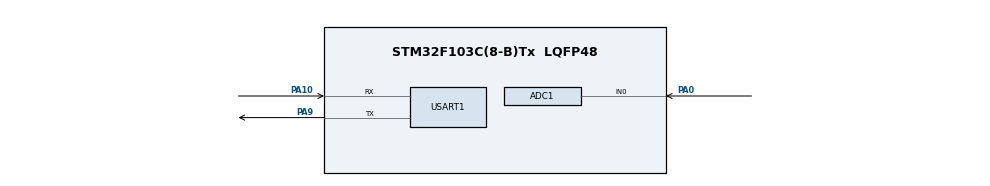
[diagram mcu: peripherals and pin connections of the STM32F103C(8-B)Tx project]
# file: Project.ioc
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ADC1.Channel-0\#ChannelRegularConversion=ADC_CHANNEL_0
ADC1.ContinuousConvMode=DISABLE
ADC1.ExternalTrigConv=ADC_EXTERNALTRIGCONV_T3_TRGO
ADC1.InjNumberOfConversion=0
ADC1.NbrOfConversion=1
ADC1.NbrOfConversionFlag=1
ADC1.Rank-0\#ChannelRegularConversion=1
ADC1.SamplingTime-0\#ChannelRegularConversion=ADC_SAMPLETIME_1CYCLE_5
ADC1.master=1
Mcu.Family=STM32F1
Mcu.Name=STM32F103C(8-B)Tx
Mcu.Package=LQFP48
NVIC.ADC1_2_IRQn=true\:0\:0\:false\:false\:true\:true\:true
NVIC.PriorityGroup=NVIC_PRIORITYGROUP_4
NVIC.TIM2_IRQn=true\:0\:0\:false\:false\:true\:true\:true
NVIC.USART1_IRQn=true\:0\:0\:false\:false\:true\:true\:true
PA0-WKUP.Signal=ADCx_IN0
PA10.Mode=Asynchronous
PA10.Signal=USART1_RX
PA13.Mode=Serial_Wire
PA13.Signal=SYS_JTMS-SWDIO
PA14.Mode=Serial_Wire
PA14.Signal=SYS_JTCK-SWCLK
PA9.Mode=Asynchronous
PA9.Signal=USART1_TX
ProjectManager.HeapSize=0x200
ProjectManager.StackSize=0x400
ProjectManager.TargetToolchain=MDK-ARM V5
RCC.APB1Freq_Value=8000000
RCC.APB2Freq_Value=8000000
SH.ADCx_IN0.0=ADC1_IN0,IN0
TIM2.CounterMode=TIM_COUNTERMODE_UP
TIM2.Period=60000
TIM2.Prescaler=8000
TIM2.TIM_MasterOutputTrigger=TIM_TRGO_RESET
TIM3.Period=1
TIM3.Prescaler=3999
TIM3.TIM_MasterOutputTrigger=TIM_TRGO_UPDATE
USART1.VirtualMode=VM_ASYNC
VP_TIM2_VS_ClockSourceINT.Mode=Internal
VP_TIM3_VS_ClockSourceINT.Mode=Internal
board=custom

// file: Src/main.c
/* USER CODE BEGIN Header */
/**
  ******************************************************************************
  * @file           : main.c
  * @brief          : Main program body
  ******************************************************************************
  * @attention
  *
  * <h2><center>&copy; Copyright (c) 2020 STMicroelectronics.
  * All rights reserved.</center></h2>
  *
  * This software component is licensed by ST under BSD 3-Clause license,
  * the "License"; You may not use this file except in compliance with the
  * License. You may obtain a copy of the License at:
  *                        opensource.org/licenses/BSD-3-Clause
  *
  ******************************************************************************
  */
/* USER CODE END Header */

#include "main.h"

/* USER CODE BEGIN Includes */
#include <stdio.h>
#include <stdlib.h>
#include <string.h>
/* USER CODE END Includes */

/* USER CODE BEGIN PM */
#define MAX_UART 16
#define COMMAND_LENGTH 5
#define ADC_BUFFER_SIZE 32
#define PEAK_THRESHOLD 2000
#define MIN_RR_INTERVAL 0.6
#define MIN_SAMPLES_RR 32

/* USER CODE END PM */

ADC_HandleTypeDef hadc1;

TIM_HandleTypeDef htim2;
TIM_HandleTypeDef htim3;

UART_HandleTypeDef huart1;

/* USER CODE BEGIN PV */
uint32_t adc_value;
char value[16];
char rxBuffer[16];

int set_sample_rate = 0;
int compute_bpm = 0;
int collect_data = 0;

int new_sample_rate = 1000;
int new_counter_period = 2;
const int counter_clk = 2000;
int computed_bpm = 0;

int detect_peak = 0;
int transmit_adc = 0;

int sample_count = 0;

uint32_t adc_values [32];
int seeker = 0, count = 0;
float prev_peak = 0, curr_peak = 0;
int num_peaks = 0;
float peak_distance = 0;

int transmit_bpm = 0;
/* USER CODE END PV */

void SystemClock_Config(void);
static void MX_GPIO_Init(void);
static void MX_ADC1_Init(void);
static void MX_USART1_UART_Init(void);
static void MX_TIM3_Init(void);
static void MX_TIM2_Init(void);

/* USER CODE BEGIN 0 */
void decode(){
	// fixed length commands
	char command [COMMAND_LENGTH+1] = {rxBuffer[0],
	rxBuffer[1], rxBuffer[2], rxBuffer[3], rxBuffer[4], '\0'};
	if(strcmp(command, "rate=") == 0){
		// set new sample rate
		char sample_rate_str [MAX_UART];
		for (int i= COMMAND_LENGTH; i<MAX_UART; i++){
				if(rxBuffer[i] != ';')
					sample_rate_str[i-COMMAND_LENGTH] = rxBuffer[i];
				else
				{
					sample_rate_str[i-COMMAND_LENGTH] = '\0';
					break;
				}
		}
		set_sample_rate = 1;
		new_sample_rate = atoi(sample_rate_str);
	} else if (strcmp(command, "hbpm;") == 0){
		// compute heart beats
		compute_bpm = 1;
	} else if (strcmp(command, "data;") == 0){
		// collect one minute of data
		collect_data = 1;
	}
	else {
		// Invalid command
	}
}
char bpm[24];
void countPeaks(){
	if((adc_values[count-1] > adc_values[count-2]) &&
		(adc_values[count-1] > adc_values[count])){    // if the previous point is a local maximamum; compare it to its neighbors
			if(adc_values[count-1] > PEAK_THRESHOLD ){  // if the previous point is above the specified threshold
						curr_peak = __HAL_TIM_GET_COUNTER(&htim2) / 1000.0; // get current time for the one minute timer
						peak_distance = curr_peak - prev_peak;              // Compute RR-Interval
						if(peak_distance > MIN_RR_INTERVAL){                // if the RR-Interval is above the minimum RR-Interval; a sort of debouncing/LPF
								num_peaks++;                                    // count it as a peak
								if (num_peaks >= 2) {
									computed_bpm = 60.0 / (peak_distance);         // 300-method for calculating bpm
									transmit_bpm = 1;
									sprintf(bpm, "bpm: %d\n\r", computed_bpm);
									HAL_UART_Transmit(&huart1, (uint8_t *)bpm, strlen(bpm), 10);
								}
								prev_peak = curr_peak;
						}
			}
		}
}
void HAL_ADC_ConvCpltCallback(ADC_HandleTypeDef* hadc){
	if(hadc->Instance == ADC1){
		adc_value = HAL_ADC_GetValue(&hadc1);
		if (transmit_adc){ // if data command triggered ADC
			sprintf(value, "%d\n\r", adc_value);
			HAL_UART_Transmit(&huart1, (uint8_t *)value, strlen(value), 10);
		}else if(detect_peak){ // if hbpm command triggered ADC
				adc_values[count] = adc_value;
				if(count <= 2) {
					countPeaks();
				}
				count = (count + 1) % MIN_SAMPLES_RR;
		}
		sample_count++;
	}
}
void HAL_UART_RxCpltCallback(UART_HandleTypeDef* huart){
	if(huart->Instance == USART1){
			decode();  // first decode instruction
			HAL_UART_Receive_IT(&huart1,(uint8_t *)rxBuffer, 16);
	}
}

void HAL_TIM_PeriodElapsedCallback(TIM_HandleTypeDef * 	htim){
	if(htim->Instance == TIM2){
		if(__HAL_TIM_GET_FLAG(&htim2, TIM_FLAG_CC1) != RESET){
			HAL_TIM_Base_Stop(&htim3);      // stop ADC trigger timer
			HAL_TIM_Base_Stop_IT(&htim2);  // stop one minute timer
		}
	}
}
/* USER CODE END 0 */

int main(void)
{

  /* MCU Configuration--------------------------------------------------------*/

  /* Reset of all peripherals, Initializes the Flash interface and the Systick. */
  HAL_Init();

  /* Configure the system clock */
  SystemClock_Config();

  /* Initialize all configured peripherals */
  MX_GPIO_Init();
  MX_ADC1_Init();
  MX_USART1_UART_Init();
  MX_TIM3_Init();
  MX_TIM2_Init();
  /* USER CODE BEGIN 2 */
	HAL_UART_Receive_IT(&huart1, (uint8_t *)rxBuffer, 16);

	HAL_ADC_Start_IT(&hadc1);

  /* USER CODE END 2 */

  /* Infinite loop */
  /* USER CODE BEGIN WHILE */
	int index = 0;
  while (1)
  {
		if(set_sample_rate){
			// change ARR value of TIM3
			new_counter_period = ((float) counter_clk / (float)new_sample_rate) - 1;
			__HAL_TIM_SET_AUTORELOAD(&htim3, new_counter_period);

			__HAL_UART_DISABLE_IT(&huart1, UART_IT_RXNE);
			set_sample_rate = 0;
			__HAL_UART_ENABLE_IT(&huart1, UART_IT_RXNE);

		}

		if(collect_data){
			sample_count = 0;
			transmit_adc = 1;
		  // start TIM3 & TIM2 for one minute
			HAL_TIM_Base_Start(&htim3);
			HAL_TIM_Base_Start_IT(&htim2);

			__HAL_UART_DISABLE_IT(&huart1, UART_IT_RXNE);
			collect_data = 0;
			__HAL_UART_ENABLE_IT(&huart1, UART_IT_RXNE);
		}

		if (compute_bpm) {
			// start adc sample rate timer; it is stopped after detecting at least one peak
			detect_peak = 1;
			computed_bpm = 0;
			curr_peak = 0;
			prev_peak = 0;
			peak_distance = 0;
			num_peaks = 0;

			HAL_TIM_Base_Start(&htim3);
			HAL_TIM_Base_Start_IT(&htim2);

			__HAL_UART_DISABLE_IT(&huart1, UART_IT_RXNE);
			compute_bpm = 0;
			__HAL_UART_ENABLE_IT(&huart1, UART_IT_RXNE);

		}

    /* USER CODE END WHILE */
  }
}

void SystemClock_Config(void)
{
  RCC_OscInitTypeDef RCC_OscInitStruct = {0};
  RCC_ClkInitTypeDef RCC_ClkInitStruct = {0};
  RCC_PeriphCLKInitTypeDef PeriphClkInit = {0};

  /** Initializes the CPU, AHB and APB busses clocks
  */
  RCC_OscInitStruct.OscillatorType = RCC_OSCILLATORTYPE_HSI;
  RCC_OscInitStruct.HSIState = RCC_HSI_ON;
  RCC_OscInitStruct.HSICalibrationValue = RCC_HSICALIBRATION_DEFAULT;
  RCC_OscInitStruct.PLL.PLLState = RCC_PLL_NONE;
  if (HAL_RCC_OscConfig(&RCC_OscInitStruct) != HAL_OK)
  {
    Error_Handler();
  }
  /** Initializes the CPU, AHB and APB busses clocks
  */
  RCC_ClkInitStruct.ClockType = RCC_CLOCKTYPE_HCLK|RCC_CLOCKTYPE_SYSCLK
                              |RCC_CLOCKTYPE_PCLK1|RCC_CLOCKTYPE_PCLK2;
  RCC_ClkInitStruct.SYSCLKSource = RCC_SYSCLKSOURCE_HSI;
  RCC_ClkInitStruct.AHBCLKDivider = RCC_SYSCLK_DIV1;
  RCC_ClkInitStruct.APB1CLKDivider = RCC_HCLK_DIV1;
  RCC_ClkInitStruct.APB2CLKDivider = RCC_HCLK_DIV1;

  if (HAL_RCC_ClockConfig(&RCC_ClkInitStruct, FLASH_LATENCY_0) != HAL_OK)
  {
    Error_Handler();
  }
  PeriphClkInit.PeriphClockSelection = RCC_PERIPHCLK_ADC;
  PeriphClkInit.AdcClockSelection = RCC_ADCPCLK2_DIV2;
  if (HAL_RCCEx_PeriphCLKConfig(&PeriphClkInit) != HAL_OK)
  {
    Error_Handler();
  }
}

static void MX_ADC1_Init(void)
{

  ADC_ChannelConfTypeDef sConfig = {0};

  /** Common config
  */
  hadc1.Instance = ADC1;
  hadc1.Init.ScanConvMode = ADC_SCAN_DISABLE;
  hadc1.Init.ContinuousConvMode = DISABLE;
  hadc1.Init.DiscontinuousConvMode = DISABLE;
  hadc1.Init.ExternalTrigConv = ADC_EXTERNALTRIGCONV_T3_TRGO;
  hadc1.Init.DataAlign = ADC_DATAALIGN_RIGHT;
  hadc1.Init.NbrOfConversion = 1;
  if (HAL_ADC_Init(&hadc1) != HAL_OK)
  {
    Error_Handler();
  }
  /** Configure Regular Channel
  */
  sConfig.Channel = ADC_CHANNEL_0;
  sConfig.Rank = ADC_REGULAR_RANK_1;
  sConfig.SamplingTime = ADC_SAMPLETIME_1CYCLE_5;
  if (HAL_ADC_ConfigChannel(&hadc1, &sConfig) != HAL_OK)
  {
    Error_Handler();
  }

}

static void MX_TIM2_Init(void)
{

  TIM_ClockConfigTypeDef sClockSourceConfig = {0};
  TIM_MasterConfigTypeDef sMasterConfig = {0};

  htim2.Instance = TIM2;
  htim2.Init.Prescaler = 8000;
  htim2.Init.CounterMode = TIM_COUNTERMODE_UP;
  htim2.Init.Period = 60000;
  htim2.Init.ClockDivision = TIM_CLOCKDIVISION_DIV1;
  htim2.Init.AutoReloadPreload = TIM_AUTORELOAD_PRELOAD_DISABLE;
  if (HAL_TIM_Base_Init(&htim2) != HAL_OK)
  {
    Error_Handler();
  }
  sClockSourceConfig.ClockSource = TIM_CLOCKSOURCE_INTERNAL;
  if (HAL_TIM_ConfigClockSource(&htim2, &sClockSourceConfig) != HAL_OK)
  {
    Error_Handler();
  }
  sMasterConfig.MasterOutputTrigger = TIM_TRGO_RESET;
  sMasterConfig.MasterSlaveMode = TIM_MASTERSLAVEMODE_DISABLE;
  if (HAL_TIMEx_MasterConfigSynchronization(&htim2, &sMasterConfig) != HAL_OK)
  {
    Error_Handler();
  }

}

static void MX_TIM3_Init(void)
{

  TIM_ClockConfigTypeDef sClockSourceConfig = {0};
  TIM_MasterConfigTypeDef sMasterConfig = {0};

  htim3.Instance = TIM3;
  htim3.Init.Prescaler = 3999;
  htim3.Init.CounterMode = TIM_COUNTERMODE_UP;
  htim3.Init.Period = 2;
  htim3.Init.ClockDivision = TIM_CLOCKDIVISION_DIV1;
  htim3.Init.AutoReloadPreload = TIM_AUTORELOAD_PRELOAD_DISABLE;
  if (HAL_TIM_Base_Init(&htim3) != HAL_OK)
  {
    Error_Handler();
  }
  sClockSourceConfig.ClockSource = TIM_CLOCKSOURCE_INTERNAL;
  if (HAL_TIM_ConfigClockSource(&htim3, &sClockSourceConfig) != HAL_OK)
  {
    Error_Handler();
  }
  sMasterConfig.MasterOutputTrigger = TIM_TRGO_UPDATE;
  sMasterConfig.MasterSlaveMode = TIM_MASTERSLAVEMODE_DISABLE;
  if (HAL_TIMEx_MasterConfigSynchronization(&htim3, &sMasterConfig) != HAL_OK)
  {
    Error_Handler();
  }

}

static void MX_USART1_UART_Init(void)
{

  huart1.Instance = USART1;
  huart1.Init.BaudRate = 115200;
  huart1.Init.WordLength = UART_WORDLENGTH_8B;
  huart1.Init.StopBits = UART_STOPBITS_1;
  huart1.Init.Parity = UART_PARITY_NONE;
  huart1.Init.Mode = UART_MODE_TX_RX;
  huart1.Init.HwFlowCtl = UART_HWCONTROL_NONE;
  huart1.Init.OverSampling = UART_OVERSAMPLING_16;
  if (HAL_UART_Init(&huart1) != HAL_OK)
  {
    Error_Handler();
  }

}

static void MX_GPIO_Init(void)
{

  /* GPIO Ports Clock Enable */
  __HAL_RCC_GPIOA_CLK_ENABLE();

}

void Error_Handler(void)
{
}

/************************ (C) COPYRIGHT STMicroelectronics *****END OF FILE****/
